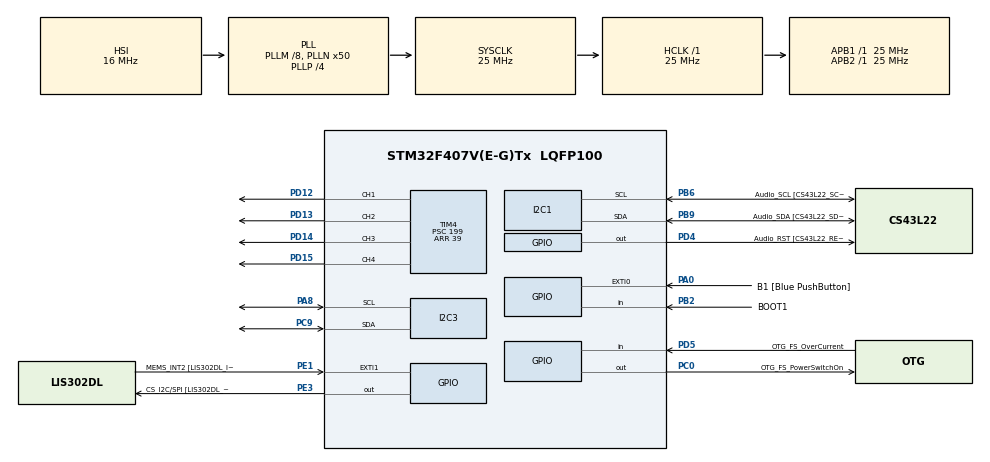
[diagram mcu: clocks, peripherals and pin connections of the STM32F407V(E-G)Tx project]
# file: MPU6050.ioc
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Mcu.Family=STM32F4
Mcu.Name=STM32F407V(E-G)Tx
Mcu.Package=LQFP100
NVIC.PriorityGroup=NVIC_PRIORITYGROUP_0
NVIC.TIM4_IRQn=true\:0\:0\:false\:false\:true\:true\:true\:true
PA0-WKUP.GPIO_Label=B1 [Blue PushButton]
PA0-WKUP.Signal=GPXTI0
PA10.GPIO_Label=OTG_FS_ID
PA10.GPIO_Mode=GPIO_MODE_AF_PP
PA10.GPIO_PuPd=GPIO_NOPULL
PA10.GPIO_Speed=GPIO_SPEED_FREQ_LOW
PA10.Signal=USB_OTG_FS_ID
PA11.GPIO_Label=OTG_FS_DM
PA11.GPIO_Mode=GPIO_MODE_AF_PP
PA11.GPIO_PuPd=GPIO_NOPULL
PA11.GPIO_Speed=GPIO_SPEED_FREQ_LOW
PA11.Signal=USB_OTG_FS_DM
PA12.GPIO_Label=OTG_FS_DP
PA12.GPIO_Mode=GPIO_MODE_AF_PP
PA12.GPIO_PuPd=GPIO_NOPULL
PA12.GPIO_Speed=GPIO_SPEED_FREQ_LOW
PA12.Signal=USB_OTG_FS_DP
PA13.GPIO_Label=SWDIO
PA13.Signal=SYS_JTMS-SWDIO
PA14.GPIO_Label=SWCLK
PA14.Signal=SYS_JTCK-SWCLK
PA4.GPIO_Label=I2S3_WS [CS43L22_LRCK]
PA4.GPIO_Mode=GPIO_MODE_AF_PP
PA4.GPIO_PuPd=GPIO_NOPULL
PA4.GPIO_Speed=GPIO_SPEED_FREQ_LOW
PA4.Signal=I2S3_WS
PA5.GPIO_Label=SPI1_SCK [LIS302DL_SCL/SPC]
PA5.GPIO_Mode=GPIO_MODE_AF_PP
PA5.GPIO_PuPd=GPIO_NOPULL
PA5.GPIO_Speed=GPIO_SPEED_FREQ_LOW
PA5.Signal=SPI1_SCK
PA6.GPIO_Label=SPI1_MISO [LIS302DL_SDO]
PA6.GPIO_Mode=GPIO_MODE_AF_PP
PA6.GPIO_PuPd=GPIO_NOPULL
PA6.GPIO_Speed=GPIO_SPEED_FREQ_LOW
PA6.Signal=SPI1_MISO
PA7.GPIO_Label=SPI1_MOSI [LIS302DL_SDA/SDI/SDO]
PA7.GPIO_Mode=GPIO_MODE_AF_PP
PA7.GPIO_PuPd=GPIO_NOPULL
PA7.GPIO_Speed=GPIO_SPEED_FREQ_LOW
PA7.Signal=SPI1_MOSI
PA8.Mode=I2C
PA8.Signal=I2C3_SCL
PA9.GPIO_Label=VBUS_FS
PA9.GPIO_Mode=GPIO_MODE_INPUT
PA9.GPIO_PuPd=GPIO_NOPULL
PA9.Signal=USB_OTG_FS_VBUS
PB10.GPIO_Label=CLK_IN [MP45DT02_CLK]
PB10.GPIO_Mode=GPIO_MODE_AF_PP
PB10.GPIO_PuPd=GPIO_NOPULL
PB10.GPIO_Speed=GPIO_SPEED_FREQ_LOW
PB10.Signal=I2S2_CK
PB2.GPIO_Label=BOOT1
PB2.GPIO_Mode=GPIO_MODE_INPUT
PB2.GPIO_PuPd=GPIO_NOPULL
PB2.Signal=GPIO_Input
PB3.GPIO_Label=SWO
PB3.Signal=SYS_JTDO-SWO
PB6.GPIO_Label=Audio_SCL [CS43L22_SCL]
PB6.GPIO_Mode=GPIO_MODE_AF_OD
PB6.GPIO_PuPd=GPIO_NOPULL
PB6.GPIO_Speed=GPIO_SPEED_FREQ_LOW
PB6.Mode=I2C
PB6.Signal=I2C1_SCL
PB9.GPIO_Label=Audio_SDA [CS43L22_SDA]
PB9.GPIO_Mode=GPIO_MODE_AF_OD
PB9.GPIO_PuPd=GPIO_NOPULL
PB9.GPIO_Speed=GPIO_SPEED_FREQ_LOW
PB9.Mode=I2C
PB9.Signal=I2C1_SDA
PC0.GPIO_Label=OTG_FS_PowerSwitchOn
PC0.GPIO_PuPd=GPIO_NOPULL
PC0.GPIO_Speed=GPIO_SPEED_FREQ_LOW
PC0.PinState=GPIO_PIN_SET
PC0.Signal=GPIO_Output
PC10.GPIO_Label=I2S3_SCK [CS43L22_SCLK]
PC10.GPIO_Mode=GPIO_MODE_AF_PP
PC10.GPIO_PuPd=GPIO_NOPULL
PC10.GPIO_Speed=GPIO_SPEED_FREQ_LOW
PC10.Signal=I2S3_CK
PC12.GPIO_Label=I2S3_SD [CS43L22_SDIN]
PC12.GPIO_Mode=GPIO_MODE_AF_PP
PC12.GPIO_PuPd=GPIO_NOPULL
PC12.GPIO_Speed=GPIO_SPEED_FREQ_LOW
PC12.Signal=I2S3_SD
PC14-OSC32_IN.GPIO_Label=PC14-OSC32_IN
PC14-OSC32_IN.Signal=RCC_OSC32_IN
PC15-OSC32_OUT.GPIO_Label=PC15-OSC32_OUT
PC15-OSC32_OUT.Signal=RCC_OSC32_OUT
PC3.GPIO_Label=PDM_OUT [MP45DT02_DOUT]
PC3.GPIO_Mode=GPIO_MODE_AF_PP
PC3.GPIO_PuPd=GPIO_NOPULL
PC3.GPIO_Speed=GPIO_SPEED_FREQ_LOW
PC3.Signal=I2S2_SD
PC7.GPIO_Label=I2S3_MCK [CS43L22_MCLK]
PC7.GPIO_Mode=GPIO_MODE_AF_PP
PC7.GPIO_PuPd=GPIO_NOPULL
PC7.GPIO_Speed=GPIO_SPEED_FREQ_LOW
PC7.Signal=I2S3_MCK
PC9.Mode=I2C
PC9.Signal=I2C3_SDA
PD12.Signal=S_TIM4_CH1
PD13.Signal=S_TIM4_CH2
PD14.Signal=S_TIM4_CH3
PD15.Signal=S_TIM4_CH4
PD4.GPIO_Label=Audio_RST [CS43L22_RESET]
PD4.GPIO_PuPd=GPIO_NOPULL
PD4.GPIO_Speed=GPIO_SPEED_FREQ_LOW
PD4.Signal=GPIO_Output
PD5.GPIO_Label=OTG_FS_OverCurrent
PD5.GPIO_Mode=GPIO_MODE_INPUT
PD5.GPIO_PuPd=GPIO_NOPULL
PD5.Signal=GPIO_Input
PE1.GPIO_Label=MEMS_INT2 [LIS302DL_INT2]
PE1.GPIO_ModeDefaultEXTI=GPIO_MODE_EVT_RISING
PE1.GPIO_PuPd=GPIO_NOPULL
PE1.Signal=GPXTI1
PE3.GPIO_Label=CS_I2C/SPI [LIS302DL_CS_I2C/SPI]
PE3.GPIO_PuPd=GPIO_NOPULL
PE3.GPIO_Speed=GPIO_SPEED_FREQ_LOW
PE3.Signal=GPIO_Output
PH0-OSC_IN.GPIO_Label=PH0-OSC_IN
PH0-OSC_IN.Signal=RCC_OSC_IN
PH1-OSC_OUT.GPIO_Label=PH1-OSC_OUT
PH1-OSC_OUT.Signal=RCC_OSC_OUT
ProjectManager.HeapSize=0x200
ProjectManager.StackSize=0x400
ProjectManager.TargetToolchain=STM32CubeIDE
RCC.48MHZClocksFreq_Value=14285714.285714285
RCC.AHBFreq_Value=25000000
RCC.APB1Freq_Value=25000000
RCC.APB1TimFreq_Value=25000000
RCC.APB2Freq_Value=25000000
RCC.APB2TimFreq_Value=25000000
RCC.CortexFreq_Value=25000000
RCC.HCLKFreq_Value=25000000
RCC.HSE_VALUE=8000000
RCC.HSI_VALUE=16000000
RCC.LSE_VALUE=32768
RCC.PLLM=8
RCC.PLLN=50
RCC.PLLP=RCC_PLLP_DIV4
RCC.PLLQ=7
RCC.SYSCLKFreq_VALUE=25000000
RCC.SYSCLKSource=RCC_SYSCLKSOURCE_PLLCLK
RCC.VCOOutputFreq_Value=100000000
SH.S_TIM4_CH1.0=TIM4_CH1,PWM Generation1 CH1
SH.S_TIM4_CH2.0=TIM4_CH2,PWM Generation2 CH2
SH.S_TIM4_CH3.0=TIM4_CH3,PWM Generation3 CH3
SH.S_TIM4_CH4.0=TIM4_CH4,PWM Generation4 CH4
TIM4.Channel-PWM\ Generation1\ CH1=TIM_CHANNEL_1
TIM4.Channel-PWM\ Generation2\ CH2=TIM_CHANNEL_2
TIM4.Channel-PWM\ Generation3\ CH3=TIM_CHANNEL_3
TIM4.Channel-PWM\ Generation4\ CH4=TIM_CHANNEL_4
TIM4.Period=39
TIM4.Prescaler=199
TIM4.Pulse-PWM\ Generation1\ CH1=16
TIM4.Pulse-PWM\ Generation2\ CH2=16
TIM4.Pulse-PWM\ Generation3\ CH3=8
TIM4.TIM_MasterOutputTrigger=TIM_TRGO_UPDATE
VP_TIM4_VS_ClockSourceINT.Mode=Internal
board=STM32F407G-DISC1

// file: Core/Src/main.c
/* USER CODE BEGIN Header */
/**
  ******************************************************************************
  * @file           : main.c
  * @brief          : Main program body
  ******************************************************************************
  * @attention
  *
  * Copyright (c) 2026 STMicroelectronics.
  * All rights reserved.
  *
  * This software is licensed under terms that can be found in the LICENSE file
  * in the root directory of this software component.
  * If no LICENSE file comes with this software, it is provided AS-IS.
  *
  ******************************************************************************
  */
/* USER CODE END Header */
#include "main.h"

/* USER CODE BEGIN Includes */
#include <math.h>

/* USER CODE END Includes */

I2C_HandleTypeDef hi2c1;
I2C_HandleTypeDef hi2c3;

TIM_HandleTypeDef htim4;

mpu6050_accel_data_t g_Accel_Data;
mpu6050_accel_offset_t error_Offset;

float roll_Angle;
int16_t kalman_roll_Angle;
int16_t roll_Angle_Filtered;
float pitch_Angle;
int16_t kalman_pitch_Angle;
int16_t pitch_Angle_Filtered;

void SystemClock_Config(void);
static void MX_GPIO_Init(void);
static void MX_I2C1_Init(void);
static void MX_I2C3_Init(void);
static void MX_TIM4_Init(void);

#define PWM_PULSE_MIN 0
#define PWM_PULSE_MAX  40

#define ANGLE_POS_MIN 0
#define ANGLE_POS_MAX 90

// Map function: re-maps a number from one range to another
long map(long x, long in_min, long in_max, long out_min, long out_max) {
    // Perform  mapping
    long result = (x - in_min) * (out_max - out_min) / (in_max - in_min) + out_min;

    // Clamp the result to the output range
    if (result > out_max) {
        result = out_max;
    } else if (result < out_min) {
        result = out_min;
    }

    return result;
}

void change_pwm_duty_cycle(uint32_t pwm_pulse, uint8_t timer_channel) {
	__HAL_TIM_SET_COMPARE(&htim4, timer_channel, pwm_pulse);
}

int main(void)
{
  float dt = 0;

  HAL_Init();
  SystemClock_Config();
  MX_GPIO_Init();
  MX_I2C1_Init();
  MX_I2C3_Init();
  MX_TIM4_Init();

  KalmanFilter kalman_Filter_Roll;
  Kalman_Filter_Init(&kalman_Filter_Roll);

  KalmanFilter kalman_Filter_Pitch;
  Kalman_Filter_Init(&kalman_Filter_Pitch);

  if (MPU6050_Init(&hi2c1, MPU6050_I2C_ADDR) != MPU6050_OK)
  {
	  Error_Handler();
  }
  else
  {
	  // Sensor working
	  MPU6050_Calibrate(&hi2c1, MPU6050_I2C_ADDR, &error_Offset, 1000);
  }

  if (MPU6050_Configure_Low_Pass_Filter(&hi2c1,DLPF_CFG_21HZ) != MPU6050_OK)
  {
	  Error_Handler();
  }

//  if (MPU6050_Configure_Gyro_Range(&hi2c1, FS_SEL_500_DEGREES) != MPU6050_OK)
//  {
//	  Error_Handler();
//  }

//  if (MPU6050_Configure_Accel_Range(&hi2c1, AFS_SEL_2G) != MPU6050_OK)
//  {
//	  Error_Handler();
//  }

  __HAL_TIM_ENABLE_IT(&htim4, TIM_IT_UPDATE);
   if( HAL_TIM_PWM_Start_IT(&htim4,TIM_CHANNEL_1) != HAL_OK)
   {
 	  Error_Handler();
   }

   if( HAL_TIM_PWM_Start_IT(&htim4,TIM_CHANNEL_2) != HAL_OK)
   {
 	  Error_Handler();
   }

   if( HAL_TIM_PWM_Start_IT(&htim4,TIM_CHANNEL_3) != HAL_OK)
   {
 	  Error_Handler();
   }

   if( HAL_TIM_PWM_Start_IT(&htim4,TIM_CHANNEL_4) != HAL_OK)
   {
 	  Error_Handler();
   }

  uint32_t previous_Tick = HAL_GetTick();

  while (1)
  {
	  uint32_t current_Tick = HAL_GetTick();
	  dt = (current_Tick - previous_Tick) / 1000.0f;
	  previous_Tick = current_Tick;

	  if (MPU6050_Read_Accelerometer_Data(&hi2c1, MPU6050_I2C_ADDR, &g_Accel_Data) != MPU6050_OK)
	  {
		  Error_Handler();
	  }

	  g_Accel_Data = MPU6050_Accelerometer_Calibration_Data(&error_Offset, &g_Accel_Data);
	  printf("Accel X: %d | Y: %d | Z: %d\r\n", g_Accel_Data.x, g_Accel_Data.y, g_Accel_Data.z);

	  roll_Angle = atan2(g_Accel_Data.y, g_Accel_Data.z) * (180.0 / M_PI);
	  roll_Angle_Filtered = (int16_t)Kalman_Filter_Get_Angle(&kalman_Filter_Roll, roll_Angle, dt);
	  printf("Roll angle:  %d\r\n", roll_Angle_Filtered);

	  pitch_Angle = atan2(g_Accel_Data.x, sqrt( (g_Accel_Data.y * g_Accel_Data.y ) + (g_Accel_Data.z * g_Accel_Data.z) )) * (180.0 / M_PI);
	  pitch_Angle_Filtered = (int16_t)Kalman_Filter_Get_Angle(&kalman_Filter_Pitch, pitch_Angle, dt);
	  printf("Pitch angle:  %d\r\n", pitch_Angle_Filtered);

	  uint8_t channel1 = (roll_Angle_Filtered < 0) ? TIM_CHANNEL_2 : TIM_CHANNEL_4;
	  uint8_t channel2 = (pitch_Angle_Filtered < 0) ? TIM_CHANNEL_1 : TIM_CHANNEL_3;

	  roll_Angle_Filtered = (roll_Angle_Filtered < 0) ? -roll_Angle_Filtered : roll_Angle_Filtered;
	  pitch_Angle_Filtered = (pitch_Angle_Filtered < 0) ? -pitch_Angle_Filtered : pitch_Angle_Filtered;

	  uint32_t pwm_pulse1 = map(roll_Angle_Filtered, ANGLE_POS_MIN, ANGLE_POS_MAX, PWM_PULSE_MIN, PWM_PULSE_MAX);
	  uint32_t pwm_pulse2 = map(pitch_Angle_Filtered, ANGLE_POS_MIN, ANGLE_POS_MAX, PWM_PULSE_MIN, PWM_PULSE_MAX);

	  change_pwm_duty_cycle(pwm_pulse1, channel1);
	  change_pwm_duty_cycle(pwm_pulse2, channel2);
  }
}

void SystemClock_Config(void)
{
  RCC_OscInitTypeDef RCC_OscInitStruct = {0};
  RCC_ClkInitTypeDef RCC_ClkInitStruct = {0};

  /** Configure the main internal regulator output voltage
  */
  __HAL_RCC_PWR_CLK_ENABLE();
  __HAL_PWR_VOLTAGESCALING_CONFIG(PWR_REGULATOR_VOLTAGE_SCALE1);

  /** Initializes the RCC Oscillators according to the specified parameters
  * in the RCC_OscInitTypeDef structure.
  */
  RCC_OscInitStruct.OscillatorType = RCC_OSCILLATORTYPE_HSI;
  RCC_OscInitStruct.HSIState = RCC_HSI_ON;
  RCC_OscInitStruct.HSICalibrationValue = RCC_HSICALIBRATION_DEFAULT;
  RCC_OscInitStruct.PLL.PLLState = RCC_PLL_ON;
  RCC_OscInitStruct.PLL.PLLSource = RCC_PLLSOURCE_HSI;
  RCC_OscInitStruct.PLL.PLLM = 8;
  RCC_OscInitStruct.PLL.PLLN = 50;
  RCC_OscInitStruct.PLL.PLLP = RCC_PLLP_DIV4;
  RCC_OscInitStruct.PLL.PLLQ = 7;
  if (HAL_RCC_OscConfig(&RCC_OscInitStruct) != HAL_OK)
  {
    Error_Handler();
  }

  /** Initializes the CPU, AHB and APB buses clocks
  */
  RCC_ClkInitStruct.ClockType = RCC_CLOCKTYPE_HCLK|RCC_CLOCKTYPE_SYSCLK
                              |RCC_CLOCKTYPE_PCLK1|RCC_CLOCKTYPE_PCLK2;
  RCC_ClkInitStruct.SYSCLKSource = RCC_SYSCLKSOURCE_PLLCLK;
  RCC_ClkInitStruct.AHBCLKDivider = RCC_SYSCLK_DIV1;
  RCC_ClkInitStruct.APB1CLKDivider = RCC_HCLK_DIV1;
  RCC_ClkInitStruct.APB2CLKDivider = RCC_HCLK_DIV1;

  if (HAL_RCC_ClockConfig(&RCC_ClkInitStruct, FLASH_LATENCY_0) != HAL_OK)
  {
    Error_Handler();
  }
}

static void MX_I2C1_Init(void)
{

  hi2c1.Instance = I2C1;
  hi2c1.Init.ClockSpeed = 100000;
  hi2c1.Init.DutyCycle = I2C_DUTYCYCLE_2;
  hi2c1.Init.OwnAddress1 = 0;
  hi2c1.Init.AddressingMode = I2C_ADDRESSINGMODE_7BIT;
  hi2c1.Init.DualAddressMode = I2C_DUALADDRESS_DISABLE;
  hi2c1.Init.OwnAddress2 = 0;
  hi2c1.Init.GeneralCallMode = I2C_GENERALCALL_DISABLE;
  hi2c1.Init.NoStretchMode = I2C_NOSTRETCH_DISABLE;
  if (HAL_I2C_Init(&hi2c1) != HAL_OK)
  {
    Error_Handler();
  }

}

static void MX_I2C3_Init(void)
{

  hi2c3.Instance = I2C3;
  hi2c3.Init.ClockSpeed = 100000;
  hi2c3.Init.DutyCycle = I2C_DUTYCYCLE_2;
  hi2c3.Init.OwnAddress1 = 0;
  hi2c3.Init.AddressingMode = I2C_ADDRESSINGMODE_7BIT;
  hi2c3.Init.DualAddressMode = I2C_DUALADDRESS_DISABLE;
  hi2c3.Init.OwnAddress2 = 0;
  hi2c3.Init.GeneralCallMode = I2C_GENERALCALL_DISABLE;
  hi2c3.Init.NoStretchMode = I2C_NOSTRETCH_DISABLE;
  if (HAL_I2C_Init(&hi2c3) != HAL_OK)
  {
    Error_Handler();
  }

}

static void MX_TIM4_Init(void)
{

  TIM_ClockConfigTypeDef sClockSourceConfig = {0};
  TIM_MasterConfigTypeDef sMasterConfig = {0};
  TIM_OC_InitTypeDef sConfigOC = {0};

  htim4.Instance = TIM4;
  htim4.Init.Prescaler = 199;
  htim4.Init.CounterMode = TIM_COUNTERMODE_UP;
  htim4.Init.Period = 39;
  htim4.Init.ClockDivision = TIM_CLOCKDIVISION_DIV1;
  htim4.Init.AutoReloadPreload = TIM_AUTORELOAD_PRELOAD_DISABLE;
  if (HAL_TIM_Base_Init(&htim4) != HAL_OK)
  {
    Error_Handler();
  }
  sClockSourceConfig.ClockSource = TIM_CLOCKSOURCE_INTERNAL;
  if (HAL_TIM_ConfigClockSource(&htim4, &sClockSourceConfig) != HAL_OK)
  {
    Error_Handler();
  }
  if (HAL_TIM_PWM_Init(&htim4) != HAL_OK)
  {
    Error_Handler();
  }
  sMasterConfig.MasterOutputTrigger = TIM_TRGO_UPDATE;
  sMasterConfig.MasterSlaveMode = TIM_MASTERSLAVEMODE_DISABLE;
  if (HAL_TIMEx_MasterConfigSynchronization(&htim4, &sMasterConfig) != HAL_OK)
  {
    Error_Handler();
  }
  sConfigOC.OCMode = TIM_OCMODE_PWM1;
  sConfigOC.Pulse = 16;
  sConfigOC.OCPolarity = TIM_OCPOLARITY_HIGH;
  sConfigOC.OCFastMode = TIM_OCFAST_DISABLE;
  if (HAL_TIM_PWM_ConfigChannel(&htim4, &sConfigOC, TIM_CHANNEL_1) != HAL_OK)
  {
    Error_Handler();
  }
  if (HAL_TIM_PWM_ConfigChannel(&htim4, &sConfigOC, TIM_CHANNEL_2) != HAL_OK)
  {
    Error_Handler();
  }
  sConfigOC.Pulse = 8;
  if (HAL_TIM_PWM_ConfigChannel(&htim4, &sConfigOC, TIM_CHANNEL_3) != HAL_OK)
  {
    Error_Handler();
  }
  sConfigOC.Pulse = 0;
  if (HAL_TIM_PWM_ConfigChannel(&htim4, &sConfigOC, TIM_CHANNEL_4) != HAL_OK)
  {
    Error_Handler();
  }
  HAL_TIM_MspPostInit(&htim4);

}

static void MX_GPIO_Init(void)
{
  GPIO_InitTypeDef GPIO_InitStruct = {0};

  /* GPIO Ports Clock Enable */
  __HAL_RCC_GPIOE_CLK_ENABLE();
  __HAL_RCC_GPIOC_CLK_ENABLE();
  __HAL_RCC_GPIOH_CLK_ENABLE();
  __HAL_RCC_GPIOA_CLK_ENABLE();
  __HAL_RCC_GPIOB_CLK_ENABLE();
  __HAL_RCC_GPIOD_CLK_ENABLE();

  /*Configure GPIO pin Output Level */
  HAL_GPIO_WritePin(CS_I2C_SPI_GPIO_Port, CS_I2C_SPI_Pin, GPIO_PIN_RESET);

  /*Configure GPIO pin Output Level */
  HAL_GPIO_WritePin(OTG_FS_PowerSwitchOn_GPIO_Port, OTG_FS_PowerSwitchOn_Pin, GPIO_PIN_SET);

  /*Configure GPIO pin Output Level */
  HAL_GPIO_WritePin(Audio_RST_GPIO_Port, Audio_RST_Pin, GPIO_PIN_RESET);

  /*Configure GPIO pin : CS_I2C_SPI_Pin */
  GPIO_InitStruct.Pin = CS_I2C_SPI_Pin;
  GPIO_InitStruct.Mode = GPIO_MODE_OUTPUT_PP;
  GPIO_InitStruct.Pull = GPIO_NOPULL;
  GPIO_InitStruct.Speed = GPIO_SPEED_FREQ_LOW;
  HAL_GPIO_Init(CS_I2C_SPI_GPIO_Port, &GPIO_InitStruct);

  /*Configure GPIO pin : OTG_FS_PowerSwitchOn_Pin */
  GPIO_InitStruct.Pin = OTG_FS_PowerSwitchOn_Pin;
  GPIO_InitStruct.Mode = GPIO_MODE_OUTPUT_PP;
  GPIO_InitStruct.Pull = GPIO_NOPULL;
  GPIO_InitStruct.Speed = GPIO_SPEED_FREQ_LOW;
  HAL_GPIO_Init(OTG_FS_PowerSwitchOn_GPIO_Port, &GPIO_InitStruct);

  /*Configure GPIO pin : PDM_OUT_Pin */
  GPIO_InitStruct.Pin = PDM_OUT_Pin;
  GPIO_InitStruct.Mode = GPIO_MODE_AF_PP;
  GPIO_InitStruct.Pull = GPIO_NOPULL;
  GPIO_InitStruct.Speed = GPIO_SPEED_FREQ_LOW;
  GPIO_InitStruct.Alternate = GPIO_AF5_SPI2;
  HAL_GPIO_Init(PDM_OUT_GPIO_Port, &GPIO_InitStruct);

  /*Configure GPIO pin : B1_Pin */
  GPIO_InitStruct.Pin = B1_Pin;
  GPIO_InitStruct.Mode = GPIO_MODE_IT_RISING;
  GPIO_InitStruct.Pull = GPIO_NOPULL;
  HAL_GPIO_Init(B1_GPIO_Port, &GPIO_InitStruct);

  /*Configure GPIO pin : I2S3_WS_Pin */
  GPIO_InitStruct.Pin = I2S3_WS_Pin;
  GPIO_InitStruct.Mode = GPIO_MODE_AF_PP;
  GPIO_InitStruct.Pull = GPIO_NOPULL;
  GPIO_InitStruct.Speed = GPIO_SPEED_FREQ_LOW;
  GPIO_InitStruct.Alternate = GPIO_AF6_SPI3;
  HAL_GPIO_Init(I2S3_WS_GPIO_Port, &GPIO_InitStruct);

  /*Configure GPIO pins : SPI1_SCK_Pin SPI1_MISO_Pin SPI1_MOSI_Pin */
  GPIO_InitStruct.Pin = SPI1_SCK_Pin|SPI1_MISO_Pin|SPI1_MOSI_Pin;
  GPIO_InitStruct.Mode = GPIO_MODE_AF_PP;
  GPIO_InitStruct.Pull = GPIO_NOPULL;
  GPIO_InitStruct.Speed = GPIO_SPEED_FREQ_LOW;
  GPIO_InitStruct.Alternate = GPIO_AF5_SPI1;
  HAL_GPIO_Init(GPIOA, &GPIO_InitStruct);

  /*Configure GPIO pin : BOOT1_Pin */
  GPIO_InitStruct.Pin = BOOT1_Pin;
  GPIO_InitStruct.Mode = GPIO_MODE_INPUT;
  GPIO_InitStruct.Pull = GPIO_NOPULL;
  HAL_GPIO_Init(BOOT1_GPIO_Port, &GPIO_InitStruct);

  /*Configure GPIO pin : CLK_IN_Pin */
  GPIO_InitStruct.Pin = CLK_IN_Pin;
  GPIO_InitStruct.Mode = GPIO_MODE_AF_PP;
  GPIO_InitStruct.Pull = GPIO_NOPULL;
  GPIO_InitStruct.Speed = GPIO_SPEED_FREQ_LOW;
  GPIO_InitStruct.Alternate = GPIO_AF5_SPI2;
  HAL_GPIO_Init(CLK_IN_GPIO_Port, &GPIO_InitStruct);

  /*Configure GPIO pins : I2S3_MCK_Pin I2S3_SCK_Pin I2S3_SD_Pin */
  GPIO_InitStruct.Pin = I2S3_MCK_Pin|I2S3_SCK_Pin|I2S3_SD_Pin;
  GPIO_InitStruct.Mode = GPIO_MODE_AF_PP;
  GPIO_InitStruct.Pull = GPIO_NOPULL;
  GPIO_InitStruct.Speed = GPIO_SPEED_FREQ_LOW;
  GPIO_InitStruct.Alternate = GPIO_AF6_SPI3;
  HAL_GPIO_Init(GPIOC, &GPIO_InitStruct);

  /*Configure GPIO pin : VBUS_FS_Pin */
  GPIO_InitStruct.Pin = VBUS_FS_Pin;
  GPIO_InitStruct.Mode = GPIO_MODE_INPUT;
  GPIO_InitStruct.Pull = GPIO_NOPULL;
  HAL_GPIO_Init(VBUS_FS_GPIO_Port, &GPIO_InitStruct);

  /*Configure GPIO pins : OTG_FS_ID_Pin OTG_FS_DM_Pin OTG_FS_DP_Pin */
  GPIO_InitStruct.Pin = OTG_FS_ID_Pin|OTG_FS_DM_Pin|OTG_FS_DP_Pin;
  GPIO_InitStruct.Mode = GPIO_MODE_AF_PP;
  GPIO_InitStruct.Pull = GPIO_NOPULL;
  GPIO_InitStruct.Speed = GPIO_SPEED_FREQ_LOW;
  GPIO_InitStruct.Alternate = GPIO_AF10_OTG_FS;
  HAL_GPIO_Init(GPIOA, &GPIO_InitStruct);

  /*Configure GPIO pin : Audio_RST_Pin */
  GPIO_InitStruct.Pin = Audio_RST_Pin;
  GPIO_InitStruct.Mode = GPIO_MODE_OUTPUT_PP;
  GPIO_InitStruct.Pull = GPIO_NOPULL;
  GPIO_InitStruct.Speed = GPIO_SPEED_FREQ_LOW;
  HAL_GPIO_Init(Audio_RST_GPIO_Port, &GPIO_InitStruct);

  /*Configure GPIO pin : OTG_FS_OverCurrent_Pin */
  GPIO_InitStruct.Pin = OTG_FS_OverCurrent_Pin;
  GPIO_InitStruct.Mode = GPIO_MODE_INPUT;
  GPIO_InitStruct.Pull = GPIO_NOPULL;
  HAL_GPIO_Init(OTG_FS_OverCurrent_GPIO_Port, &GPIO_InitStruct);

  /*Configure GPIO pin : MEMS_INT2_Pin */
  GPIO_InitStruct.Pin = MEMS_INT2_Pin;
  GPIO_InitStruct.Mode = GPIO_MODE_EVT_RISING;
  GPIO_InitStruct.Pull = GPIO_NOPULL;
  HAL_GPIO_Init(MEMS_INT2_GPIO_Port, &GPIO_InitStruct);

}

void Error_Handler(void)
{
  __disable_irq();
  while (1)
  {
  }
}
